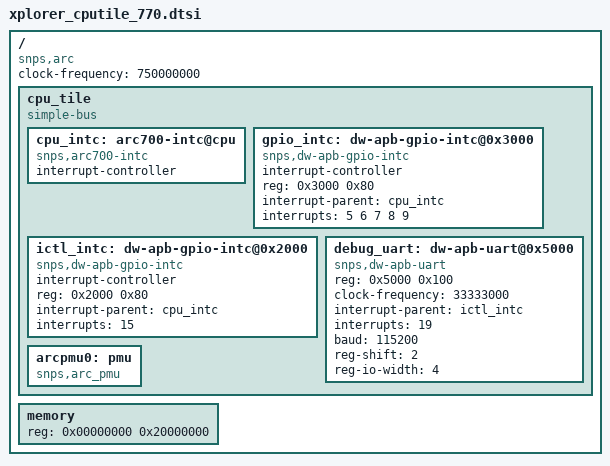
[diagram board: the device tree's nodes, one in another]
/*
 * Copyright (C) 2013 Synopsys, Inc. (www.synopsys.com)
 *
 * This program is free software; you can redistribute it and/or modify
 * it under the terms of the GNU General Public License version 2 as
 * published by the Free Software Foundation.
 */

/*
 * Device tree for ARC Xplorer 770D/EM6/AS221 CPU tile
 */

/ {
	compatible = "snps,arc";
	clock-frequency = <750000000>;	/* 750 MHZ */
	#address-cells = <1>;
	#size-cells = <1>;

	cpu_tile {
		compatible = "simple-bus";
		#address-cells = <1>;
		#size-cells = <1>;

		ranges = <0x00000000 0xf0000000 0x10000000>;

		cpu_intc: arc700-intc@cpu {
			compatible = "snps,arc700-intc";
			interrupt-controller;
			#interrupt-cells = <1>;
		};

		/* this GPIO block serves as an interrupt controller and
		   uses multiple interrupts on the ARC700 */
		gpio_intc: dw-apb-gpio-intc@0x3000 {
			compatible = "snps,dw-apb-gpio-intc";
			interrupt-controller;
			reg = < 0x3000 0x80 >;
			#interrupt-cells = <1>;
			interrupt-parent = <&cpu_intc>;
			interrupts = < 5 6 7 8 9 >;
		};

		/* this GPIO block serves as an interrupt controller and
		   ORs all interrupts, so that only one interrupt on ARC700
		   is used */
		ictl_intc: dw-apb-gpio-intc@0x2000 {
			compatible = "snps,dw-apb-gpio-intc";
			interrupt-controller;
			reg = < 0x2000 0x80 >;
			#interrupt-cells = <1>;
			interrupt-parent = <&cpu_intc>;
			interrupts = <15>;
		};

		debug_uart: dw-apb-uart@0x5000 {
			compatible = "snps,dw-apb-uart";
			reg = <0x5000 0x100>;
			clock-frequency = <33333000>;
			interrupt-parent = <&ictl_intc>;
			interrupts = <19>;
			baud = <115200>;
			reg-shift = <2>;
			reg-io-width = <4>;
		};

		arcpmu0: pmu {
			compatible = "snps,arc_pmu";
		};
	};

	memory {
		#address-cells = <1>;
		#size-cells = <1>;
		ranges = <0x00000000 0x80000000 0x40000000>;
		device_type = "memory";
		reg = <0x00000000 0x20000000>;	/* 512MiB */
	};
};
